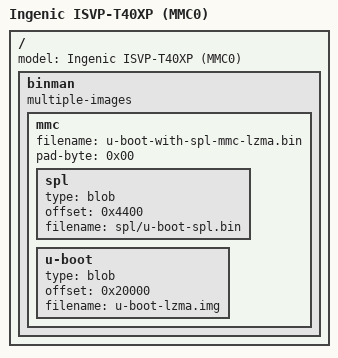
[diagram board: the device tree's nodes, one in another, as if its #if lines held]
// SPDX-License-Identifier: GPL-2.0+
/*
 * Binman image description for the Ingenic ISVP-T40XP SFC-NAND boot.
 *
 * T40XP uses SPI-NAND (DDR3 256 MiB, vs T40NN's DDR2 NOR + 128 MiB).
 * The bootrom's NAND boot path expects no INGE block at SPL offset
 * 0x100 (vendor SPI-NAND SPL ships with all zeros there). Since the
 * etype now defaults to no-INGE (only emits when
 * `ingenic,inge-descriptors` is supplied), we simply omit
 * descriptors. The `ingenic,no-inge` boolean below is retained as
 * the NAND-style 64-byte block alignment switch (the vendor
 * `spl_pad_to_block.c` rule for the secure-boot hash module).
 *
 * The custom NAND U-Boot loader in arch/mips/mach-xburst/t40/sfc_nand.c
 * reads the legacy mkimage header + LZMA payload from NAND offset
 * T40_NAND_UBOOT_OFFSET (0x80000), so keep U-Boot at 0x80000 here.
 * The 64 KiB SPL window is comfortable for DM-in-SPL builds.
 *
 * `ingenic,min-spl-length` covers the BSS region: with DM-in-SPL the
 * SPL ends before SPL_BSS_START_ADDR + SPL_BSS_MAX_SIZE = 0x80016000,
 * so we pad the SPL file (with 0xff) to that length, so the bootrom
 * caches enough SRAM to back BSS during board_init_f.
 */

#include "t40-isvp-uboot-common.dtsi"

/ {
	binman: binman {
		multiple-images;
	};
};

&binman {
#if defined(CONFIG_SPL_MMC)
	/*
	 * MSC/SD-card boot image (isvp_t40xp_msc0). The SPL carries the
	 * mask-ROM "MSPL" magic (start.S, gated on SPL_MMC) at offset 0 and
	 * is used as a plain blob - no etype, no INGE/min-spl-length: the
	 * mask ROM defaults the SD load to 0x19000, which already covers
	 * BSS. The ROM reads the SPL from SD sector 34 (0x4400); the SPL
	 * loads U-Boot from SYS_MMCSD_RAW_MODE_U_BOOT_SECTOR (0x100 = byte
	 * 0x20000).
	 */
	mmc {
		filename = "u-boot-with-spl-mmc-lzma.bin";
		pad-byte = <0x00>;

		spl {
			type = "blob";
			offset = <0x4400>;
			filename = "spl/u-boot-spl.bin";
		};

		u-boot {
			type = "blob";
			offset = <0x20000>;
			filename = "u-boot-lzma.img";
		};
	};
#else
	u-boot-spl-t40xp {
		filename = "u-boot-spl-t40xp.bin";

		ingenic-t31-spl {
			filename = "spl/u-boot-spl.bin";
			ingenic,no-inge;
			ingenic,min-spl-length = <0x16000>;
		};
	};

	flash {
		filename = "u-boot-with-spl-lzma.bin";
		pad-byte = <0xff>;

		spl {
			type = "blob";
			offset = <0x0>;
			filename = "u-boot-spl-t40xp.bin";
		};

		u-boot {
			type = "blob";
			offset = <0x80000>;
			filename = "u-boot-lzma.img";
		};
	};
#endif
};

#if defined(CONFIG_SPL_MMC)
/ {
	/*
	 * The MSC/SD-card boot config (isvp_t40xp_msc0) reuses the SFC-NAND
	 * board .dts, whose model is annotated "(SFC NAND)". Correct it to
	 * reflect the actual boot medium.
	 */
	model = "Ingenic ISVP-T40XP (MMC0)";
};
#endif
